# NUC100DN_v1 register map
File version: 1.0
Registers are 32-bit, read-write, reset 0x0 unless marked. A register's access mark holds for its fields unless they carry their own. Offsets are from the block's base; [hi:lo] are bit positions; {n}, {i} and the like mark numbered series.

## PS2 — PS2 Register Map
Base 0x40100000
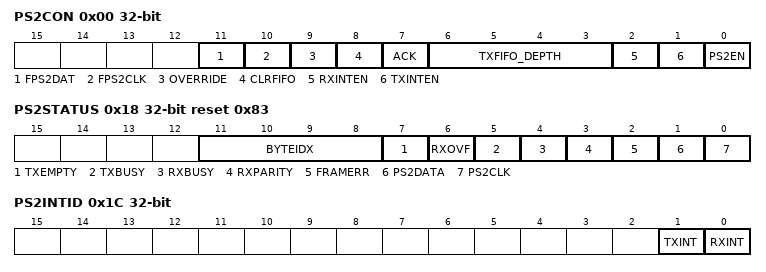
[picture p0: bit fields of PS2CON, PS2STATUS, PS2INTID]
0x00 PS2CON — PS/2 Control Register
  [11] FPS2DAT — Force PS2DATA Line. It forces PS2DATA high or low regardless of the internal state of the device controller if OVERRIDE is set to 1.
    0=Force PS2DATA low; 1=Force PS2DATA high
  [10] FPS2CLK — Force PS2CLK Line. It forces PS2CLK line high or low regardless of the internal state of the device controller if OVERRIDE is set to 1.
    0=Force PS2CLK line low; 1=Force PS2CLK line high
  [9] OVERRIDE — Software Override PS2 CLK/DATA Pin State
    0=PS2CLK and PS2DATA pins are controlled by internal state machine; 1=PS2CLK and PS2DATA pins are controlled by software
  [8] CLRFIFO — Clear TX FIFO. Write 1 to this bit to terminate device to host transmission. The TXEMPTY bit in PS2STATUS bit will be set to 1 and pointer BYTEIDEX is reset to 0 regardless there is residue data in buffer or not. The buffer content is not been cleared.
    0=Not active; 1=Clear FIFO
  [7] ACK — Acknowledge Enable Bit
    0=Always send acknowledge to host at 12th clock for host to device communication; 1=If parity bit error or stop bit is not received correctly, acknowledge bit will not be sent to host at 12th clock
  [6:3] TXFIFO_DEPTH — Transmit Data FIFO Depth. There are 16 bytes buffer for data transmit. Software can define the FIFO depth from 1 to 16 bytes depends on application needs.
    0=1 byte; 1=2 bytes; 14=15 bytes; 15=16 bytes
  [2] RXINTEN — Receive Interrupt Enable Bit
    0=Data receive complete interrupt Disabled; 1=Data receive complete interrupt Enabled
  [1] TXINTEN — Transmit Interrupt Enable Bit
    0=Data transmit complete interrupt Disabled; 1=Data transmit complete interrupt Enabled
  [0] PS2EN — PS/2 Device Enable Bit
    0=PS/2 device controller Disabled; 1=PS/2 device controller Enabled
{0x4+4i} PS2TXDATA{i} (i=0..3) — PS/2 Transmit Data Register {i}
  [31:0] PS2TXDATAx — Transmit Data. Writing data to this register starts in device to host communication if bus is in IDLE state. Software must enable PS2EN before writing data to TX buffer.
0x14 PS2RXDATA ro — PS/2 Receive Data Register
  [7:0] RXDATA — Received Data. For host to device communication, after acknowledge bit is sent, the received data is copied from receive shift register to PS2RXDATA register. CPU must read this register before next byte reception complete, otherwise the data will be overwritten and RXOVF bit in PS2STATUS[6] will be set to 1.
0x18 PS2STATUS reset 0x83
  [11:8] BYTEIDX ro — Byte Index (Read Only). It indicates which data byte in transmit data shift register. When all data in FIFO is transmitted and it will be cleared to 0.
    0=DATA Transmit is TXDATA0[7:0]; 1=DATA Transmit is TXDATA0[15:8]; 2=DATA Transmit is TXDATA0[23:16]; 3=DATA Transmit is TXDATA0[31:24]; 4=DATA Transmit is TXDATA1[7:0]; 5=DATA Transmit is TXDATA1[15:8]; 6=DATA Transmit is TXDATA1[23:16]; 7=DATA Transmit is TXDATA1[31:24]; 8=DATA Transmit is TXDATA2[7:0]; 9=DATA Transmit is TXDATA2[15:8]; 10=DATA Transmit is TXDATA2[23:16]; 11=DATA Transmit is TXDATA2[31:24]; 12=DATA Transmit is TXDATA3[7:0]; 13=DATA Transmit is TXDATA3[15:8]; 14=DATA Transmit is TXDATA3[23:16]; 15=DATA Transmit is TXDATA3[31:24]
  [7] TXEMPTY ro — TX FIFO Empty (Read Only). When software writes data to PS2TXDATA0-3, the TXEMPTY bit is cleared to 0 immediately if PS2EN is enabled. When transmitted data byte number is equal to FIFODEPTH then TXEMPTY bit is set to 1.
    0=There is data to be transmitted; 1=FIFO is empty
  [6] RXOVF — RX Buffer Overwrite. Note: This bit can be cleared by writing '1' to it.
    0=No overwrite; 1=Data in PS2RXDATA register is overwritten by new received data
  [5] TXBUSY ro — Transmit Busy (Read Only). This bit indicates that the PS/2 device is currently sending data.
    0=Idle; 1=Currently sending data
  [4] RXBUSY ro — Receive Busy (Read Only). This bit indicates that the PS/2 device is currently receiving data.
    0=Idle; 1=Currently receiving data
  [3] RXPARITY ro — Received Parity (Read Only). This bit reflects the parity bit for the last received data byte (odd parity).
  [2] FRAMERR — Frame Error. For host to device communication, this bit sets to 1 if STOP bit (logic 1) is not received. If frame error occurs, the PS2_DATA line may keep at low state after 12th clock. At this moment, software overrides PS2CLK to send clock till PS2DATA release to high state. After that, device sends a "Resend" command to host. Note: This bit can be cleared by writing '1' to it.
    0=No frame error; 1=Frame error occur
  [1] PS2DATA — DATA Pin State. This bit reflects the status of the PS2DATA line after synchronizing and sampling.
  [0] PS2CLK — CLK Pin State. This bit reflects the status of the PS2CLK line after synchronizing.
0x1C PS2INTID — PS/2 Interrupt Identification Register
  [1] TXINT — Transmit Interrupt. This bit is set to 1 after STOP bit is transmitted. Interrupt occur if TXINTEN bit is set to 1. Note: This bit can be cleared by writing '1' to it.
    0=No interrupt; 1=Transmit interrupt occurs
  [0] RXINT — Receive Interrupt. This bit is set to 1 when acknowledge bit is sent for Host to device communication. Interrupt occurs if RXINTEN bit is set to 1. Note: This bit can be cleared by writing '1' to it.
    0=No interrupt; 1=Receive interrupt occurs
